# CY8C4247LQI_BL483 register map
File version: 0.1
PSoC 4200 BLE
Registers are 32-bit, read-write, no defined reset value unless marked. A register's access mark holds for its fields unless they carry their own. Offsets are from the block's base; lines under a group give offsets from that group; [hi:lo] are bit positions; {n}, {i} and the like mark numbered series; 'fields as' and 'values as' point back to an identical list; <NAME> marks a mode.

## Memory map
0x00000000 AppDelay
0x00000000 UART_XB — Serial Communication Block
0x00000000 Timer_LED

## AppDelay
Base 0x00000000
0x400F0000 AppDelay_COUNTER 24-bit — UDB.A0 - Current Down Counter Value
0x400F0020 AppDelay_PERIOD 24-bit — UDB.D0 - Assigned Period
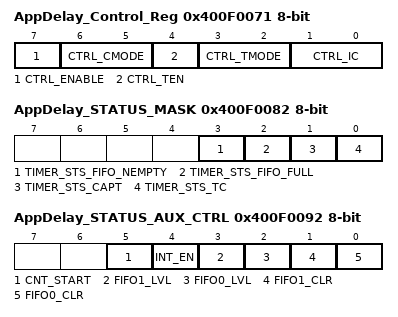
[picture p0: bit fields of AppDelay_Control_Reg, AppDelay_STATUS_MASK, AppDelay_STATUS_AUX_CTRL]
0x400F0071 AppDelay_Control_Reg 8-bit — UDB Control Register - Assigned Control Register Value
  [7] CTRL_ENABLE — Enable the Timer
  [6:5] CTRL_CMODE — Capture Mode
  [4] CTRL_TEN — Trigger Enable Bit
  [3:2] CTRL_TMODE — Trigger Mode
  [1:0] CTRL_IC — Interrupt Count
0x400F0082 AppDelay_STATUS_MASK 8-bit — UDB Status bits Interrupt Mask Enable Register
  [3] TIMER_STS_FIFO_NEMPTY ro — FIFO Empty status
  [2] TIMER_STS_FIFO_FULL ro — FIFO Full Status
  [1] TIMER_STS_CAPT ro — Enables the Interrupt on Capture
  [0] TIMER_STS_TC ro — Enables the Interrupt on TC
0x400F0092 AppDelay_STATUS_AUX_CTRL 8-bit — UDB Auxilliary Control Register
  [5] CNT_START — FIFO0 clear
    0=E_CNT_START0 (Disable counter); 1=E_CNT_START1 (Enable counter)
  [4] INT_EN
    0=E_INT_EN0 (Interrupt disabled); 1=E_INT_EN1 (Interrupt enabled)
  [3] FIFO1_LVL — FIFO level
    0=E_FIFO_LVL_0 (FIFO LVL: input mode: FIFO not full; output mode: FIFO not empty); 1=E_FIFO_LVL_1 (FIFO LVL: input mode: FIFO at least 1/2 empty; output mode: FIFO at least 1/2 full)
  [2] FIFO0_LVL — FIFO level
    values as FIFO1_LVL
  [1] FIFO1_CLR — FIFO1 clear
    0=E_FIFO_CLR_0 (Normal FIFO operation); 1=E_FIFO_CLR_1 (Clear FIFO state)
  [0] FIFO0_CLR — FIFO0 clear
    values as FIFO1_CLR

## Timer_LED
Base 0x00000000
0x40200108 COUNTER — Current counter value
0x4020010C CC — Compare / capture value
0x40200110 CC_BUF — Compare / capture buffer value
0x40200114 PERIOD — Period value
0x40200118 PERIOD_BUF — Period buffer value
